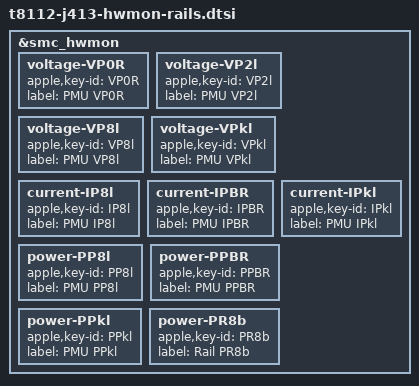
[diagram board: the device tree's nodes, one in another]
// SPDX-License-Identifier: GPL-2.0+ OR MIT
/*
 * T8112 J413 PMU rail channels the J473 SMC does not publish. The rails
 * both boards have are in t8112-hwmon-rails.dtsi, where the key naming is
 * explained. The consumers of these outputs are not mapped.
 */

&smc_hwmon {
	voltage-VP0R {
		apple,key-id = "VP0R";
		label = "PMU VP0R";
	};

	voltage-VP2l {
		apple,key-id = "VP2l";
		label = "PMU VP2l";
	};

	voltage-VP8l {
		apple,key-id = "VP8l";
		label = "PMU VP8l";
	};

	voltage-VPkl {
		apple,key-id = "VPkl";
		label = "PMU VPkl";
	};

	current-IP8l {
		apple,key-id = "IP8l";
		label = "PMU IP8l";
	};

	current-IPBR {
		apple,key-id = "IPBR";
		label = "PMU IPBR";
	};

	current-IPkl {
		apple,key-id = "IPkl";
		label = "PMU IPkl";
	};

	power-PP8l {
		apple,key-id = "PP8l";
		label = "PMU PP8l";
	};

	power-PPBR {
		apple,key-id = "PPBR";
		label = "PMU PPBR";
	};

	power-PPkl {
		apple,key-id = "PPkl";
		label = "PMU PPkl";
	};

	power-PR8b {
		apple,key-id = "PR8b";
		label = "Rail PR8b";
	};
};
